# DCC_MSS_DCC_52B00000h register map
Vendor: Texas Instruments
Peripheral module from a debugger description file (folder AM263P).
Registers are 32-bit, read-write, reset 0x0 unless marked. A register's access mark holds for its fields unless they carry their own. Offsets are as the file gives them; lines under a group give offsets from that group; [hi:lo] are bit positions; {n}, {i} and the like mark numbered series; 'fields as' and 'values as' point back to an identical list; <NAME> marks a mode.

## MSS_DCC
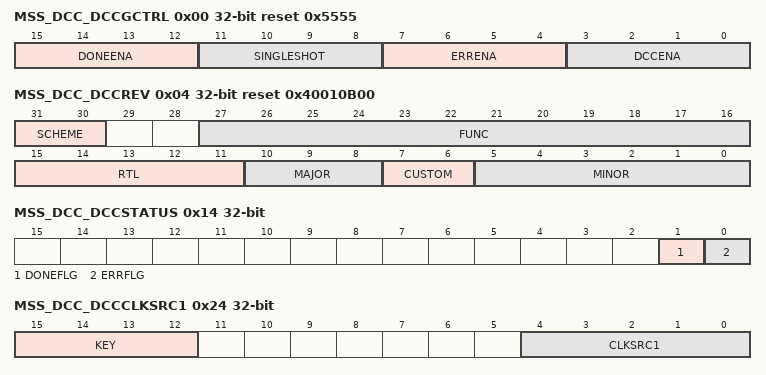
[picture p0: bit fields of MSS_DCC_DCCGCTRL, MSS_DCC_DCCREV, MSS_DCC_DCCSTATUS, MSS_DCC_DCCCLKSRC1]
0x00 MSS_DCC_DCCGCTRL reset 0x5555 — Starts / stops the counters. Clears the error signal.
  [15:12] DONEENA — The DONEENA bit enables/disables the done interrupt signal, but has no effect on the done status flag in DCCSTAT register.User, privilege, and debug mode (read):0101= the done signal is disabledothers = the done signal is enabledPrivilege and debug mode (write):0101= Disable done signal generation others 1010 = Enable done signal generation. It is recommended to write 1010 to enable each feature to avoid single soft errors.
  [11:8] SINGLESHOT — The SINGLESHOT bit enables/disables repetitive operation of the DCC.User, privilege, and debug mode (read):1010= stop counting when counter0 and valid0 both reach zero1011= stop counting when counter1 reaches zeroothers = continuously repeat (until error)Privilege and debug mode (write):1010= stop counting when counter0 and valid0 both reach zero1011= stop counting when counter1 reaches zeroothers = continuously repeat (until error)
  [7:4] ERRENA — The ERRENA bit enables/disables the error signal. User, privilege, and debug mode (read):0101= the error signal is disabled others = the error signal is enabled Privilege and debug mode (write): 0101= disable error signal generation others 1010 = enable error signal generation. It is recommended to write 1010 to enable each feature to avoid single soft errors.
  [3:0] DCCENA — The DCCENA bit starts and stops the operation of the dcc.User, privilege, and debug mode (read):0101= counters are stoppedothers = counters are runningPrivilege and debug mode (write):0101= stop counters and error-checkingothers 1010 = load the counters with their seed values and begin counting. It is recommended to write 1010 to enable each feature to avoid single soft errors.
0x04 MSS_DCC_DCCREV ro reset 0x40010B00 — Specifies the module version.
  [31:30] SCHEME — User, privilege, and debug mode (read): Returns 01.Privilege and debug mode (write): Writes have no effect.
  [27:16] FUNC — Reflects software-compatability. If there is no level of software compatability, a unique func number is assigned; for compatible modules, the same number is maintained.User, privilege, and debug mode (read): 0x0Privilege and debug mode (write): Writes have no effect.
  [15:11] RTL — Incremented for releases due to spec changes or post-release design changes. Reset to 0 when either MAJOR or MINOR is incremented.User, privilege, and debug mode (read): 0x1Privilege and debug mode (write): Writes have no effect.
  [10:8] MAJOR — Represents major changes to the module (e.g. entirely new features are added/changed). The major revision number for this module.User, privilege, and debug mode (read): 0x2Privilege and debug mode (write): Writes have no effect.
  [7:6] CUSTOM — Indicates a special version of the module. May not be supported by standard software.User, privilege, and debug mode (read): 0x0Privilege and debug mode (write): Writes have no effect.
  [5:0] MINOR — Represents minor changes to the module (e.g. enhancements to existing features). The minor revision number for this module.User, privilege, and debug mode (read): 0x4Privilege and debug mode (write): Writes have no effect.
0x08 MSS_DCC_DCCCNTSEED0 — Seed value for the counter attached to clock source 0
  [19:0] COUNTSEED0 — This field contains the seed value that gets loaded into counter 0 (clock source 0).User, privilege, and debug mode (read):Returns the current seed value for counter 0.Privilege and debug mode (write):Sets the current seed value for counter 0.NOTE - Operating the DCC with 0 in the COUNTSEED0 register will result in undefined operation.
0x0C MSS_DCC_DCCVALIDSEED0 — Seed value for the timeout counter attached to clock source 0.
  [15:0] VALIDSEED0 — This field contains the seed value that gets loaded into the valid duration counter for clock source 0.User, privilege, and debug mode (read):Returns the current seed value for VALID0.Privilege and debug mode (write):Sets the current seed value for VALID0.NOTE - Operating the DCC with 0 in the VALIDSEED0 register will result in undefined operation. VALID0 defines a window in which COUNT1 expires. This window is meant to be at least four cycles wide. Do not program a value less than 4 into the VALID0 register.
0x10 MSS_DCC_DCCCNTSEED1 — Seed value for the counter attached to clock source 1.
  [19:0] COUNTSEED1 — This field contains the seed value that gets loaded into counter 1 (clock source 1).User, privilege, and debug mode (read):Returns the current seed value for counter 1.Privilege and debug mode (write):Sets the current seed value for counter 1.NOTE - Operating the DCC with 0 in the COUNTSEED1 register will result in undefined operation.
0x14 MSS_DCC_DCCSTATUS access not given — Specifies the status of the DCC Module.
  [1] DONEFLG — Indicates when single-shot mode is complete without error. Writing a 1 to this bit clears the flag.User, privilege, and debug mode (read):0 = single-shot mode is not done1 = single-shot mode is donePrivilege and debug mode (write):0 = no effect1 = clear the done flag (access R/W1TC)
  [0] ERRFLG — Indicates whether or not an error has occured. Writing a 1 to this bit clears the flag.User, privilege, and debug mode (read):0 = an error has not occurred1 = an error has occurredPrivilege and debug mode (write):0 = no effect1 = clear the error flag (access R/W1TC)
0x18 MSS_DCC_DCCCNT0 ro — Value of the counter attached to clock source 0.
  [19:0] COUNT0 — This field contains the current value of counter 0.User, privilege, and debug mode (read):Returns either the current value of Count 0 or the Count 0 FIFO location, depending upon DCCGCTRL2.FIFO_READ.Privilege and debug mode (write):Writes have no effect.NOTE - Reads of the counter value may not be exact since the read operation is synchronized to the vbus clock.
0x1C MSS_DCC_DCCVALID0 ro — Value of the valid counter attached to clock source 0.
  [15:0] VALID0 — This field contains the current value of valid counter 0.User, privilege, and debug mode (read):Returns either the current value of Valid 0 or the Valid 0 FIFO location depending upon DCCGCTRL2.FIFO_READ.Privilege and debug mode (write):writes have no effect.NOTE - Reads of the counter value may not be exact since the read operation is synchronized to the vbus clock.
0x20 MSS_DCC_DCCCNT1 ro — Value of the counter attached to clock source 1.
  [19:0] COUNT1 — This field contains the current value of counter 1.User, privilege, and debug mode (read):Returns either the current value of Count 1 or the Count 1 FIFO location depending upon DCCGCTRL2.FIFO_READ 1.Privilege and debug mode (write):writes have no effect.NOTE - Reads of the counter value may not be exact since the read operation is synchronized to the vbus clock.
0x24 MSS_DCC_DCCCLKSRC1 — Selects the clock source for counter 1.
  [15:12] KEY — This field enables or disables clock source selection for counter 1.User, privilege, and debug mode (read):Returns the current value of the key.Privilege and debug mode (write):Sets the key value.Key values:1010 The CLKSRC field selects the clock source for counter 1.others: Clock source selection is disabled.
  [4:0] CLKSRC1 — This field specifies the clock source for counter 1, when the KEY field enables this feature.User, privilege, and debug mode (read):Returns the current value of CLKSRC1.Privilege and debug mode (write):Sets the value of CLKSRC1.
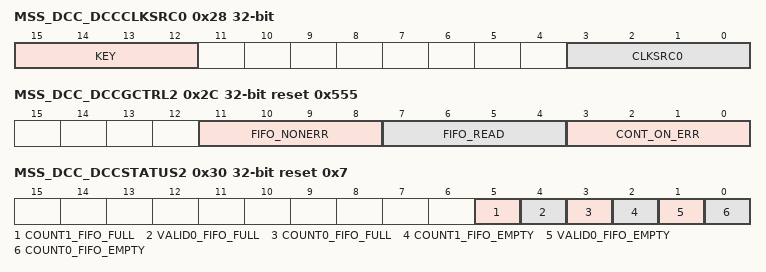
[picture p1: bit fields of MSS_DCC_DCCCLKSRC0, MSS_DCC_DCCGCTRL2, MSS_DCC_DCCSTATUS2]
0x28 MSS_DCC_DCCCLKSRC0 — Selects the clock source for counter 0.
  [15:12] KEY — This field enables or disables clock source selection for counter 0.User, privilege, and debug mode (read):Returns the current value of the key.Privilege and debug mode (write):Sets the key value.Key values:1010 The CLKSRC field selects the clock source for counter 0.others: Clock source selection is disabled.
  [3:0] CLKSRC0 — This field specifies the clock source for counter 0, when the KEY field enables this feature.User, privilege, and debug mode (read):Returns the current value of CLKSRC0.Privilege and debug mode (write):Sets the value of CLKSRC0.
0x2C MSS_DCC_DCCGCTRL2 reset 0x555 — Allows configuring different modes of operation for DCC.
  [11:8] FIFO_NONERR — Enables/disables FIFO writes without the error event on completion of comparison window.User, privilege, and debug mode (read):Returns the current field value.Privilege and debug mode (write):Sets the value of field value.Source values:0101 Counter values are captured to non-full FIFO only upon Error event.Others 1010 : Write counter values to non-full FIFO upon completion of comparison window regardless of error or not. It is recommended to write 1010 to avoid single soft errors.
  [7:4] FIFO_READ — Enables the counter read registers reflect FIFO output instead of the live counter value.User, privilege, and debug mode (read):Returns the current field value.Privilege and debug mode (write):Sets the value of field value.Source values:0101 Counter value is read directly.Others 1010 : Counters FIFO output is read. It is recommended to write 1010 to avoid single soft errors.
  [3:0] CONT_ON_ERR — Continues to next window of comparison despite the error condition.User, privilege, and debug mode (read):Returns the current field value.Privilege and debug mode (write):Sets the value of field value.Enable values:0101 Comparison and counter reload is stopped from advancing if error is detected.Others 1010:Counters get reloaded with seed and continue counting despite the error condition. It is recommended to write 1010 to avoid single soft errors.
0x30 MSS_DCC_DCCSTATUS2 ro reset 0x7 — Specifies the status of the DCC FIFOs.
  [5] COUNT1_FIFO_FULL — Count1 FIFO Full. Indicates whether Count1 FIFO is full.User, privilege, and debug mode (read):0:Count1 FIFO is not full1:Count1 FIFO is full.Privilege and debug mode (write): Writes have no effect.
  [4] VALID0_FIFO_FULL — Valid0 FIFO Full. Indicates whether Valid0 FIFO is full.User, privilege, and debug mode (read):0:Valid0 FIFO is not full1:Valid0 FIFO is full.Privilege and debug mode (write): Writes have no effect.
  [3] COUNT0_FIFO_FULL — Count0 FIFO Full. Indicates whether Count0 FIFO is full.User, privilege, and debug mode (read):0:Count0 FIFO is not full1:Count0 FIFO is full.Privilege and debug mode (write): Writes have no effect.
  [2] COUNT1_FIFO_EMPTY — Count1 FIFO Empty. Indicates whether Count1 FIFO is empty.User, privilege, and debug mode (read):0:Count1 FIFO is not empty1:Count1 FIFO is empty.Privilege and debug mode (write): Writes have no effect.
  [1] VALID0_FIFO_EMPTY — Valid0 FIFO Empty. Indicates whether Valid0 FIFO is empty.User, privilege, and debug mode (read):0:Valid0 FIFO is not empty1:Valid0 FIFO is empty.Privilege and debug mode (write): Writes have no effect.
  [0] COUNT0_FIFO_EMPTY — Count0 FIFO Empty. Indicates whether Count0 FIFO is empty.User, privilege, and debug mode (read):0:Count0 FIFO is not empty1:Count0 FIFO is empty.Privilege and debug mode (write): Writes have no effect.
0x34 MSS_DCC_DCCERRCNT — Counts number of errors since last clear.
  [9:0] ERRCNT — Counts the number of errors after the last write to this register or reset. If reached terminal count the count freezes. User needs to clear it.
